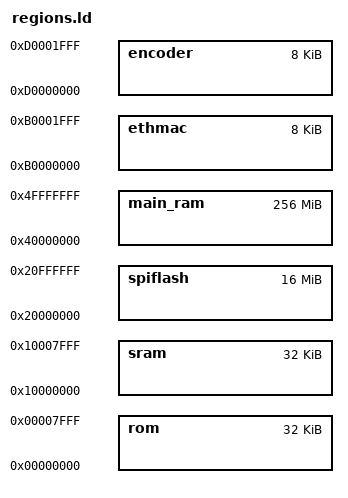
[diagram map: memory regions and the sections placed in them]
MEMORY {
	rom : ORIGIN = 0x00000000, LENGTH = 0x00008000
	sram : ORIGIN = 0x10000000, LENGTH = 0x00008000
	spiflash : ORIGIN = 0x20000000, LENGTH = 0x01000000
	main_ram : ORIGIN = 0x40000000, LENGTH = 0x10000000
	ethmac : ORIGIN = 0xb0000000, LENGTH = 0x00002000
	encoder : ORIGIN = 0xd0000000, LENGTH = 0x00002000
}
